# APM32L07x register map
File version: 1.0
CPU: CM0+ r0p0, little endian, MPU, no FPU, 4 interrupt priority bits
Registers are 32-bit, read-write, reset 0x0 unless marked. A register's access mark holds for its fields unless they carry their own. Offsets are from the block's base; [hi:lo] are bit positions; {n}, {i} and the like mark numbered series; 'fields as' and 'values as' point back to an identical list.

## DBGMCU — Debug support
Base 0x40015800
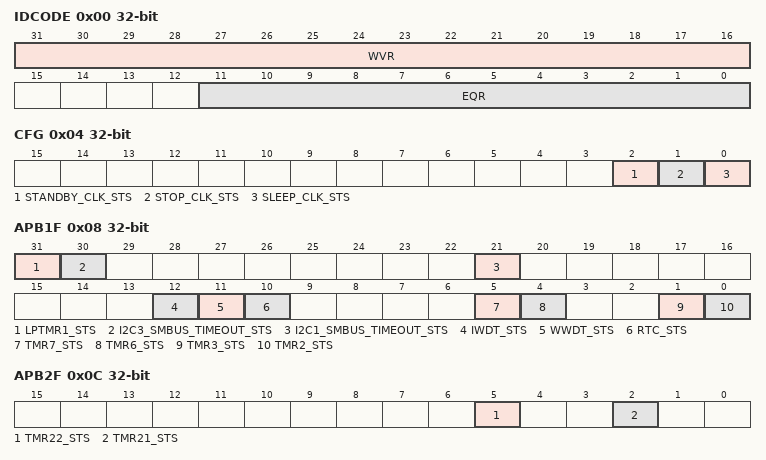
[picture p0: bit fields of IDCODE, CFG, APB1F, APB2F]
0x00 IDCODE ro — MCU Device ID Code Register
  [31:16] WVR — Wafer Version Recognition
  [11:0] EQR — Equipment Recognition
0x04 CFG — Debug MCU Configuration Register
  [2] STANDBY_CLK_STS — Configure clock status when MCU is debugged in standby mode
  [1] STOP_CLK_STS — Configure clock status when MCU is debugged in stop mode
  [0] SLEEP_CLK_STS — Configure clock status when MCU is debugged in sleep mode
0x08 APB1F — APB Low Freeze Register
  [31] LPTMR1_STS — Configure LPTMR1 Work Status When Core is in Halted
  [30] I2C3_SMBUS_TIMEOUT_STS — Configure I2C3_SMBUS_TIMEOUT Work Status When Core is in Halted
  [21] I2C1_SMBUS_TIMEOUT_STS — Configure I2C1_SMBUS_TIMEOUT Work Status When Core is in Halted
  [12] IWDT_STS — Configure Independent Watchdog Work Status When Core is in Halted
  [11] WWDT_STS — Configure Window Watchdog Work Status When Core is in Halted
  [10] RTC_STS — Configure RTC Work Status When Core is in Halted
  [5] TMR7_STS — ConfigureTimer7 Work Status When Core is in Halted
  [4] TMR6_STS — ConfigureTimer6 Work Status When Core is in Halted
  [1] TMR3_STS — ConfigureTimer3 Work Status When Core is in Halted
  [0] TMR2_STS — ConfigureTimer2 Work Status When Core is in Halted
0x0C APB2F — APB High Freeze Register
  [5] TMR22_STS — ConfigureTimer22 Work Status When Core is in Halted
  [2] TMR21_STS — ConfigureTimer21 Work Status When Core is in Halted

## DMA — Direct memory access controller
Base 0x40020000
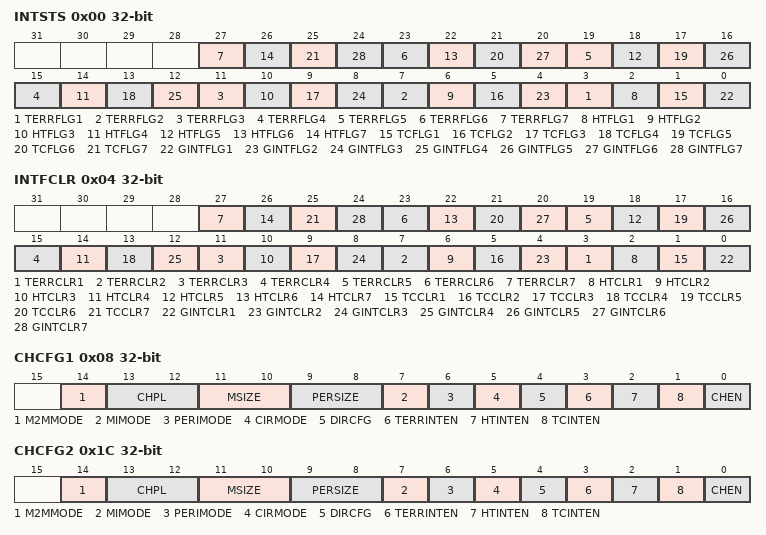
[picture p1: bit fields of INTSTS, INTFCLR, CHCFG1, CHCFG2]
0x00 INTSTS ro — interrupt status register
  [4n-1] TERRFLG{n} (n=1..7) — Channel x transfer error flag (x = 1 ..7)
  [4n-2] HTFLG{n} (n=1..7) — Channel x half transfer flag (x = 1 ..7)
  [4n-3] TCFLG{n} (n=1..7) — Channel x transfer complete flag (x = 1 ..7)
  [4n-4] GINTFLG{n} (n=1..7) — Channel x global interrupt flag (x = 1 ..7)
0x04 INTFCLR wo — interrupt flag clear register
  [4n-1] TERRCLR{n} (n=1..7) — Channel x transfer error clear (x = 1 ..7)
  [4n-2] HTCLR{n} (n=1..7) — Channel x half transfer clear (x = 1 ..7)
  [4n-3] TCCLR{n} (n=1..7) — Channel x transfer complete clear (x = 1 ..7)
  [4n-4] GINTCLR{n} (n=1..7) — Channel x global interrupt clear (x = 1 ..7)
0x08 CHCFG1 — channel x configuration register
  [14] M2MMODE — Memory to memory mode
  [13:12] CHPL — Channel priority level
  [11:10] MSIZE — Memory size
  [9:8] PERSIZE — Peripheral size
  [7] MIMODE — Memory increment mode
  [6] PERIMODE — Peripheral increment mode
  [5] CIRMODE — Circular mode
  [4] DIRCFG — Data transfer direction
  [3] TERRINTEN — Transfer error interrupt enable
  [2] HTINTEN — Half transfer interrupt enable
  [1] TCINTEN — Transfer complete interrupt enable
  [0] CHEN — Channel enable
0x0C CHNDATA1 — channel x number of data register
  [15:0] NDATAT — Number of data to transfer
0x10 CHPADDR1 — channel x peripheral address register
  [31:0] PERADDR — Peripheral address
{0x0+0x14*i} CHMADDR{i} (i=1..7) — channel x memory address register
  [31:0] MEMADDR — Memory address
0x1C CHCFG2 — channel x configuration register
  fields as CHCFG1
0x20 CHNDATA2 — channel x number of data register
  [15:0] NDATAT — Number of data to transfer
0x24 CHPADDR2 — channel x peripheral address register
  [31:0] PERADDR — Peripheral address
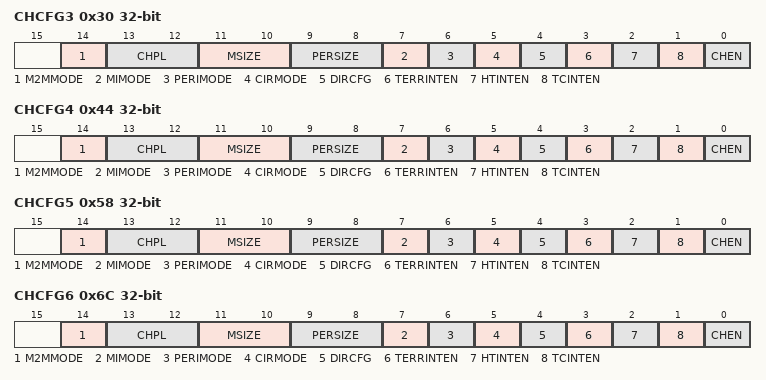
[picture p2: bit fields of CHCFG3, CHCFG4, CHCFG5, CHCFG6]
0x30 CHCFG3 — channel x configuration register
  fields as CHCFG1
0x34 CHNDATA3 — channel x number of data register
  [15:0] NDATAT — Number of data to transfer
0x38 CHPADDR3 — channel x peripheral address register
  [31:0] PERADDR — Peripheral address
0x44 CHCFG4 — channel x configuration register
  fields as CHCFG1
0x48 CHNDATA4 — channel x number of data register
  [15:0] NDATAT — Number of data to transfer
0x4C CHPADDR4 — channel x peripheral address register
  [31:0] PERADDR — Peripheral address
0x58 CHCFG5 — channel x configuration register
  fields as CHCFG1
0x5C CHNDATA5 — channel x number of data register
  [15:0] NDATAT — Number of data to transfer
0x60 CHPADDR5 — channel x peripheral address register
  [31:0] PERADDR — Peripheral address
0x6C CHCFG6 — channel x configuration register
  fields as CHCFG1
0x70 CHNDATA6 — channel x number of data register
  [15:0] NDATAT — Number of data to transfer
0x74 CHPADDR6 — channel x peripheral address register
  [31:0] PERADDR — Peripheral address
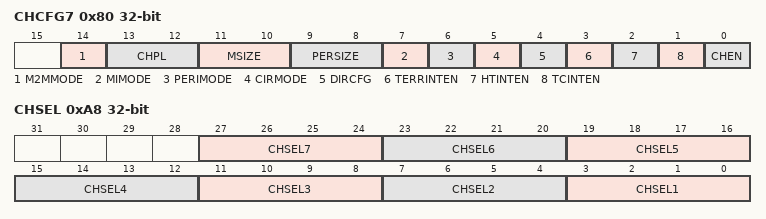
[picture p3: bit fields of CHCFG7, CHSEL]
0x80 CHCFG7 — channel x configuration register
  fields as CHCFG1
0x84 CHNDATA7 — channel x number of data register
  [15:0] NDATAT — Number of data to transfer
0x88 CHPADDR7 — channel x peripheral address register
  [31:0] PERADDR — Peripheral address
0xA8 CHSEL — channel selection register
  [4n-1:4n-4] CHSEL{n} (n=1..7) — DMA channel {n} selection
